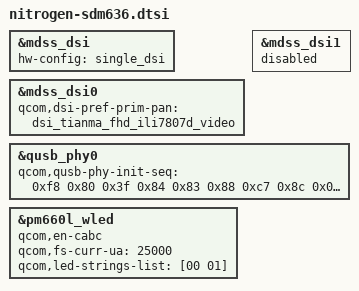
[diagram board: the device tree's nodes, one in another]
/* Copyright (c) 2016-2017, The Linux Foundation. All rights reserved.
 * Copyright (C) 2020 XiaoMi, Inc.
 *
 * This program is free software; you can redistribute it and/or modify
 * it under the terms of the GNU General Public License version 2 and
 * only version 2 as published by the Free Software Foundation.
 *
 * This program is distributed in the hope that it will be useful,
 * but WITHOUT ANY WARRANTY; without even the implied warranty of
 * MERCHANTABILITY or FITNESS FOR A PARTICULAR PURPOSE.  See the
 * GNU General Public License for more details.
 */

#include "nitrogen-c-sdm660.dtsi"
/ {
};

&mdss_dsi {
	hw-config = "single_dsi";
};

&mdss_dsi0 {
	qcom,dsi-pref-prim-pan = <&dsi_tianma_fhd_ili7807d_video>;
};

&mdss_dsi1 {
	status = "disabled";
};

&qusb_phy0 {
	qcom,qusb-phy-init-seq = <0xf8 0x80
				0x3f 0x84
				0x83 0x88
				0xc7 0x8c
				0x01 0x90
				0x30 0x08
				0x79 0x0c
				0x21 0x10
				0x14 0x9c
				0x9f 0x1c
				0x00 0x18>;
};

&pm660l_wled {
	qcom,en-cabc;
	qcom,fs-curr-ua = <25000>;
	qcom,led-strings-list = [00 01];
};
